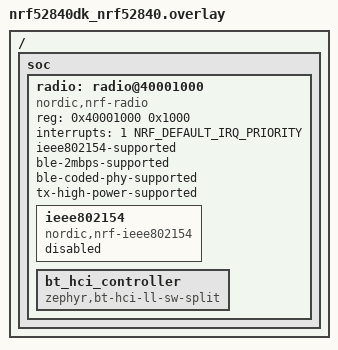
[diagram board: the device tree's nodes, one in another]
/{
    soc {
        radio: radio@40001000 {
			compatible = "nordic,nrf-radio";
			reg = <0x40001000 0x1000>;
			interrupts = <1 NRF_DEFAULT_IRQ_PRIORITY>;
			status = "okay";
			ieee802154-supported;
			ble-2mbps-supported;
			ble-coded-phy-supported;
			tx-high-power-supported;

			ieee802154: ieee802154 {
				compatible = "nordic,nrf-ieee802154";
				status = "disabled";
			};

			/* Note: In the nRF Connect SDK the SoftDevice Controller
			 * is added and set as the default Bluetooth Controller.
			 */
			bt_hci_controller: bt_hci_controller {
				compatible = "zephyr,bt-hci-ll-sw-split";
				status = "okay";
			};
		};
    };
};


